# AE512F80F5582LS_CM55_HE_View register map
Vendor: Alif Semiconductor; Series: E5; File version: 1.0
CPU: CM55 r1p0, selectable endian, MPU, FPU, double-precision FPU, DSP, VTOR, 8 interrupt priority bits, 1 SAU regions
Registers are 32-bit, read-write, reset 0x0 unless marked. A register's access mark holds for its fields unless they carry their own. Offsets are from the block's base; [hi:lo] are bit positions; lines under a group give offsets from that group; {n}, {i} and the like mark numbered series.

## DAC120
Base 0x49028000
Same registers: DAC121 0x49029000
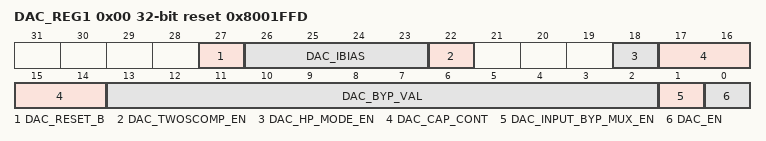
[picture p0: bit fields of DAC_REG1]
0x00 DAC_REG1 reset 0x8001FFD (reset mask 0xF8783FFF) — REG1 DAC Control Register
  [27] DAC_RESET_B — DAC reset:
    0=Reset asserted; 1=Reset released
  [26:23] DAC_IBIAS — Trims buffer output current (HP mode): From 0000 = 0 uA to 1111 = 1.5 mA Default is 1111 for DAC120 and 0000 for DAC121 Step size ~100 uA
  [22] DAC_TWOSCOMP_EN — Converts two's complement to unsigned binary data:
    0=Input data is unsigned; 1=Input data is two's complement signed (conversion to unsigned enable)
  [18] DAC_HP_MODE_EN — DAC high-performance mode enable.
    0=Low-power (LP) mode (default for DAC121); 1=High-performance (HP) mode (default for DAC120)
  [17:14] DAC_CAP_CONT — Trims HP mode capacitance compensation: From xx00 = 2 pF to xx11 = 8 pF Step size = 2 pF Default is xx11 = 8 pF for DAC120 and xx00 for DAC121 Bits [17-16] = Don't care
  [13:2] DAC_BYP_VAL — DAC input data in bypass mode
  [1] DAC_INPUT_BYP_MUX_EN — Selects DAC input data source:
    0=DAC_IN register; 1=DAC_REG1[DAC_BYP_VAL] bitfield (bypass mode)
  [0] DAC_EN — DAC enable:
    0=DAC is disabled; 1=DAC is enabled
0x04 DAC_IN — DAC Input Value Register
  [11:0] VALUE — Value used by DAC analog portion for conversion.

## HWSEM0
Base 0x4902E000
Same registers: HWSEM{n} {0x4902E000+0x10*n} (n=1..15)
0x00 HWSEM_REQ_REG reset not defined — Request register
  [31:0] REQ_ACQ — Request a HWSEM module by writing the processor ID into this field. Check the status of the HWSEM request by reading this field.
0x04 HWSEM_REL_REG reset not defined — Release register
  [31:0] REL_CHK — Release the HWSEM by writing the processor ID into this field. Check the current HWSEM count by reading this field.
0x08 HWSEM_RST_REG wo reset not defined — Reset register
  [31:0] RST — Reset the semaphore count and current master ID.

## EVTRTR0
Base 0x49035000
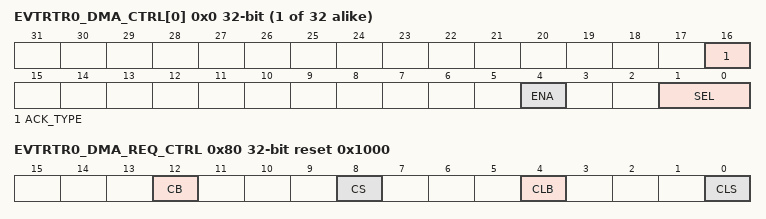
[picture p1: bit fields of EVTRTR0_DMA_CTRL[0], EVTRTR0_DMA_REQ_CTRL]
{0x0+4i} EVTRTR0_DMA_CTRL[{i}] (i=0..31) — DMA/Event Router Control and Status Register (n)
  [16] ACK_TYPE ro — DMA handshake type status for DMA peripheral
    0=Peripheral completes the REQ-ACK handshake with DMA controller. Event Router passing through REQ-ACK between DMA controller and peripheral.; 1=Event Router completes the REQ-ACK handshake with DMA controller. Peripheral raises DMA request without responding to ACK from DMA controller.
  [4] ENA — DMA channel enable
    0=Disable DMA channel; 1=Enable DMA channel
  [1:0] SEL — Select one channel from the four input groups
    {v}=Select group {v} (v=0..3)
0x80 EVTRTR0_DMA_REQ_CTRL reset 0x1000 — DMA Request Control Register
  [all] fields
    0=Disable; 1=Enable
  [12] CB — Enable DMA request on DMACBREQ (DMAC Burst Request) Note: It is recommended to enable all DMA requests on the burst request line (DMACBREQ). For single transfer, the number of beats in a burst should be set to 1 (DMA_CCRn[SRC_BURST_LEN] = 0x0).
  [8] CS — Enable DMA request on DMACSREQ (DMAC Single Request) Note: It is recommended to enable all DMA requests on the burst request line (DMACBREQ), even for single transfer.
  [4] CLB — Enable DMA request on DMACLBREQ (DMAC Last Burst Request) Note: Do not use. The current implementation does not support transfers from a peripheral with an unspecified length ('peripheral length management').
  [0] CLS — Enable DMA request on DMACLSREQ (DMAC Last Single Request) Note: Do not use. The current implementation does not support transfers from a peripheral with an unspecified length ('peripheral length management').
0x90 EVTRTR0_DMA_ACK_TYPE0 reset 0xFFFFFF00 — DMA Handshake Type Register 0
  [31:0] ACK — Select DMA handshake type for DMA group #0
0x94 EVTRTR0_DMA_ACK_TYPE1 reset 0xFF3FF300 — DMA Handshake Type Register 1
  [31:0] ACK — Select DMA handshake type for DMA group #1
0x98 EVTRTR0_DMA_ACK_TYPE2 reset 0xC3FF0000 — DMA Handshake Type Register 2
  [31:0] ACK — Select DMA handshake type for DMA group #2
0x9C EVTRTR0_DMA_ACK_TYPE3 — DMA Handshake Type Register 3
  [31:0] ACK — Select DMA handshake type for DMA group #3
